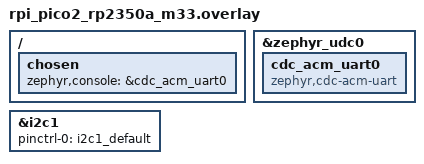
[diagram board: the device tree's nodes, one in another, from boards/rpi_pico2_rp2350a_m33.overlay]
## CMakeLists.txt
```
cmake_minimum_required(VERSION 3.20.0)

# Select our board 
set(BOARD rpi_pico2/rp2350a/m33)


# Find/Select cmake package 'Zephyr' 
find_package(Zephyr)

# This is only used by IntelliSense inside VS Code 
set(CMAKE_EXPORT_COMPILE_COMMANDS ON)

# For using west flash with picoprobe
# set(OPENOCD "openocd")
# set(OPENOCD_DEFAULT_PATH "/usr/local/share/openocd/scripts")

# Define project name
project(pico2pico-prototype)

# Add include directory 
target_include_directories(app PRIVATE src/inc)

# Add source files
FILE(GLOB SRC_FILES "src/*.c")
target_sources(app PRIVATE ${SRC_FILES})
```

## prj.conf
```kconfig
CONFIG_SERIAL=y
CONFIG_CONSOLE=y
CONFIG_UART_CONSOLE=y
CONFIG_STDOUT_CONSOLE=y
CONFIG_UART_LINE_CTRL=y

CONFIG_USB_DEVICE_STACK_NEXT=y
CONFIG_CDC_ACM_SERIAL_INITIALIZE_AT_BOOT=y
CONFIG_CDC_ACM_SERIAL_PRODUCT_STRING="USBD console sample"

CONFIG_I2C=y
CONFIG_I2C_TARGET=y
```

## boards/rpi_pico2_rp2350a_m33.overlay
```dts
/ {
    chosen {
		zephyr,console = &cdc_acm_uart0;
	};
};

&zephyr_udc0 {
	cdc_acm_uart0: cdc_acm_uart0 {
		compatible = "zephyr,cdc-acm-uart";
	};
};


&i2c1 {
	pinctrl-0 = <&i2c1_default>;
    status = "okay";
};
```

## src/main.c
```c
#include "handler_interface.h"
#include <zephyr/drivers/i2c.h>
#include <zephyr/kernel.h>
#include <zephyr/sys/printk.h>

static const struct device *bus = DEVICE_DT_GET(DT_NODELABEL(i2c1));
int handle_read(uint8_t reg, uint8_t *out) {
    printk("[read] From 0x%02x\n", reg);
    *out = reg;
    return 0;
}

int handle_write(uint8_t reg, uint8_t val) {
    printk("[write] To 0x%02x with 0x%02x\n", reg, val);
    return 0;
}

int main(void) {

    printk("Target start\n");
    handler_config_t cfg = (handler_config_t){
        .handle_read = handle_read,
        .handle_write = handle_write,
        .address = 0x60,
    };
    int ret;
    if ((ret = register_target_with_handlers(bus, &cfg)) != 0) {
        printk("register: %d\n", ret);
        while (true) {
            printk("ERR: %d\n", ret);
        }
    }

    while (1) {
        k_msleep(1000);
    }
}
```

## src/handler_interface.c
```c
#include "handler_interface.h"
#include <zephyr/drivers/i2c.h>
#include <zephyr/sys/printk.h>

enum COMM_STATE { COMM_STOPPED,
                  COMM_WRITE_REQUESTED,
                  COMM_ADDR_RECIVED };

typedef struct comm_state_machine {
    enum COMM_STATE state;
    uint8_t addr;
} comm_state_machine_t;

static comm_state_machine_t comm = (comm_state_machine_t){
    .state = COMM_STOPPED,
    .addr = 0,
};

static handler_config_t *registered_config = NULL;

static int write_requested_cb(struct i2c_target_config *config) {
    printk("write requested\n");
    comm.state = COMM_WRITE_REQUESTED;
    return 0;
}

static int write_received_cb(struct i2c_target_config *config, uint8_t val) {
    printk("write received: 0x%02x\n", val);

    switch (comm.state) {
    case COMM_WRITE_REQUESTED:
        comm.addr = val;
        comm.state = COMM_ADDR_RECIVED;
        break;

    case COMM_ADDR_RECIVED:
        registered_config->handle_write(comm.addr, val);
        break;
    default:
        printk("Unexpected write received\n");
        break;
    }

    return 0;
}

static int read_requested_cb(struct i2c_target_config *config, uint8_t *out) {
    printk("read request: 0x%02x\n", *out);

    if (comm.state == COMM_ADDR_RECIVED) {
        registered_config->handle_read(comm.addr, out);
    } else {
        printk("Unexpected read: 0x%02x\n", *out);
    }

    return 0;
}

static int read_processed_cb(struct i2c_target_config *config, uint8_t *val) {
    // TOOO:figure out what all this means
    printk("read processed: 0x%02x\n", *val);
    *val = 0x43;
    return 0;
}

static int stop_cb(struct i2c_target_config *config) {
    // printk("sample target stop callback\n");
    comm.state = COMM_STOPPED;
    return 0;
}

static void error_cb(struct i2c_target_config *config, enum i2c_error_reason error_code) {
    printk("target error %d\n", error_code);
}

static struct i2c_target_callbacks callbacks = {
    .write_requested = write_requested_cb,
    .write_received = write_received_cb,
    .read_requested = read_requested_cb,
    .read_processed = read_processed_cb,
    .stop = stop_cb,
    .error = error_cb};

static struct i2c_target_config i2c_cfg = {
    .address = 0x60,
    .callbacks = &callbacks,
    .flags = 0,
};

int register_target_with_handlers(const struct device *dev, handler_config_t *cfg) {
    if (cfg == NULL || registered_config != NULL) {
        return -EINVAL;
    }

    i2c_cfg.address = cfg->address;

    int ret = i2c_target_register(dev, &i2c_cfg);
    if (ret != 0) {
        return ret;
    }

    registered_config = cfg;
    return 0;
}
```
